# FSI_RX_FSI_RX_CFG_50290000h register map
Vendor: Texas Instruments
Registers are 16-bit, read-write, reset 0x0 unless marked. A register's access mark holds for its fields unless they carry their own. Offsets are as the file gives them; [hi:lo] are bit positions.

## FSI_RX_CFG (part 2 of 2)
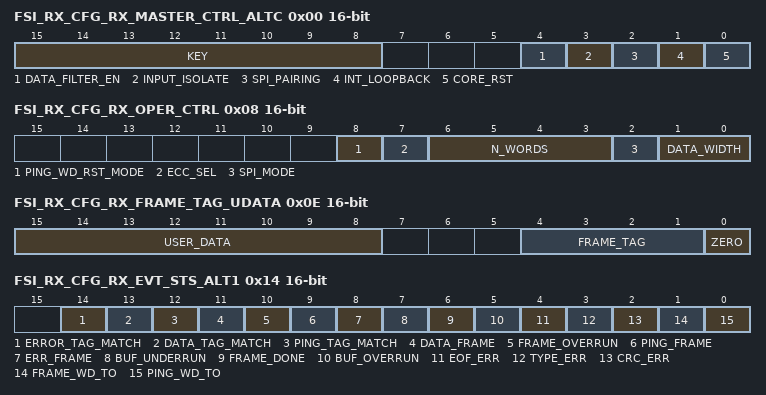
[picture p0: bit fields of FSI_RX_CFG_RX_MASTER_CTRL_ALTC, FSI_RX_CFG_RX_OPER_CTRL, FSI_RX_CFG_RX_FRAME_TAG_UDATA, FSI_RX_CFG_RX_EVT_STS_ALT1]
0x00 FSI_RX_CFG_RX_MASTER_CTRL_ALTC access per field — Receive master control register.
  [15:8] KEY wo — Write Key. In order to write to this register, 0xA5 must be written to this field at the same time. Otherwise, writes are ignored. The key is cleared immediately after Writing, so it must be written again for every change to this register.
  [4] DATA_FILTER_EN rw — Data Filter Enable Bit. 0h[R/W] = Data filtering is disabled. 1h[R/W] = Data filtering is enabled.
  [3] INPUT_ISOLATE rw — When set to 1, the FSI RX inputs [RXCLK, RXD0 and RXD1] will be isolated from what is driven from the device pins and will be held at inactive level of '1'.This isolation facilitates the user to switch the RX inputs to a different set of device pins and hence any potential glitch that could occur during the process of switching will not effect the RX module itself.
  [2] SPI_PAIRING rw — Clock Pairing for SPI-like Behavior Enable bit This bit enables the internal clock pairing with the FSI TX module. This feature internally connects the TXCLK to RXCLK allowing the FSI TX module, acting as a SPI master, to clock data into the receiver and out of the transmitter like a standard SPI module. This configuration is valid when the Module is in SPI mode only [RX_OPER_CTRL.SPI_MODE = 1] 0h[R/W] = SPI clock pairing is not enabled. 1h[R/W] = SPI clock pairing is enabled. The RXCLK will be internally connected to the TXCLK of the corresponding FSI module. Note: The KEY field must contatin 0xA5 for any write to this bit to take effect.
  [1] INT_LOOPBACK rw — Internal Loopback Enable bit This bit enables the internal loopback functionality of the FSI receiver. By enabling this bit, a mux will select the signals coming directly from the corresponding FSI transmitter module rather than from the pins. 0h[R/W] = Internal loopback is disabled. The FSI RX module will receive signals coming from the pins. 1h[R/W] = Internal loopback is enabled. The FSI RX module will receive signals from the directly from FSI TX module rather than the pins. Note: The KEY field must contatin 0xA5 for any write to this bit to take effect.
  [0] CORE_RST rw — Receiver Controller Core Reset bit This bit controls the receiver master core reset. In order to receive any frame, this bit must be cleared. Note: For reset to take affect, the FSI RX module must be held in reset for at least 4 SYSCLK cycles. 0h[R/W] = Receiver core is not in reset and can receive frames. 1h[R/W] = Receiver core is held in reset. Note: The KEY field must contatin 0xA5 for any write to this bit to take effect.
0x08 FSI_RX_CFG_RX_OPER_CTRL — Receive operation control register.
  [8] PING_WD_RST_MODE — Ping Watchdog Timeout Mode Select bit This bit selects the mode by which the ping watchdog counter is reset. The watchdog counter can be reset and restarted only by ping frames or by any received frame. 0h[R/W] = The ping watchdog counter will reset and restart only by ping frames. 1h[R/W] = The ping watchdog counter will reset and restart by any received frame.
  [7] ECC_SEL — ECC Data Width Select bit This bit selects between whether the ECC computation is done on 16-bit or 32-bit words. 0h[R/W] = 32-bit ECC is used. 1h[R/W] = 16-bit ECC is used.
  [6:3] N_WORDS — Number of Words to Receive This field defines the number of words which will be received in a DATA_N_WORD frame. This is a user-defined field that must match the corresponding field in the transmitter. Set this bitfield to be one less than the number of words to be received. This value is only applicable when the frame type received is DATA_N_WORD. 0h[R/W] = 1 data word frame [16-bit data]. 1h[R/W] = 2 data word frame [32-bit data]. .. Fh [R/W] = 16 data word frame [256-bit data].
  [2] SPI_MODE — SPI Mode Enable bit This bit enables and disables the SPI compatibility mode of the FSI RX. The received data must be formatted as an FSI frame in order for the data to properly be received. SPI compatibility mode will allow FSI RX to receive data that is sent using SPI signal format. Refer to the applicable section in the FSI TRM chapter for more information. 0h[R/W] = FSI is in normal mode of operation. 1h[R/W] = FSI is operating in SPI compatibility mode.
  [1:0] DATA_WIDTH — Receive Data Width Select bit These bits decide the number of data lines used for receiving data. 0h[R/W] = Data will be received on one data line, RXD0. 1h[R/W] = Data will be received on two data lines, RXD0 and RXD1. 2h3h[R/W] = Reserved
0x0C FSI_RX_CFG_RX_FRAME_INFO ro — Receive frame control register.
  [3:0] FRAME_TYPE — Received Frame Type This field indicates the type of frame that was successfully received last. 0000b[R/W] = A ping frame was received 0100b[R/W] = A DATA_1_WORD frame was received [16-bit data]. 0101b[R/W] = A DATA_2_WORD frame was received [32-bit data]. 0110b[R/W] = A DATA_4_WORD frame was received [64-bit data]. 0111b[R/W] = A DATA_6_WORD frame was received [96-bit data]. 0011b[R/W] = A DATA_N_WORD frame was received. The N_WORD field will determine the number of words [1 to 16] to be sent. The number of words received must equal the value programmed in RX_OPER_CTRL.N_WORDS. 1111b[R/W] = An error frame was received. This frame can be used during error conditions or any condition where the transmitter wants to signal the receiver for attention. However, the user software is at liberty to use this for any purpose. 0001b0010b and1000bthrough1110bare Reserved and should not be used.
0x0E FSI_RX_CFG_RX_FRAME_TAG_UDATA ro — Receive frame tag and user data register.
  [15:8] USER_DATA — Received User Data This field contains the 8-bit user data field of the last successfully received frame.
  [4:1] FRAME_TAG — Received Frame Tag This field contains the 4-bit frame tag from the last successfully received frame. This is intentionally shifted into bits 4:1 so that the register can be used as a 32-bit address index based on the received tag.
  [0] ZERO — Zero bit This bit will always read as 0. This is intentionally provided to create a 32-bit offset if required. Using the FRAME_TAG and ZERO bits of this register [bits 4:0], application software can directly index into an array of 32-bit data.
0x10 FSI_RX_CFG_RX_DMA_CTRL — Receive DMA event control register.
  [0] DMA_EVT_EN — DMA Event Enable bit This bit will enable a DMA Event to be generated upon the completion of a frame reception. 0h[R/W] = A DMA event will not be generated. 1h[R/W] = A DMA event will be generated upon the reception of a frame. Note: The DMA event will only be generated for data frames.
0x14 FSI_RX_CFG_RX_EVT_STS_ALT1 ro — Receive event and error status flag register.
  [14] ERROR_TAG_MATCH — Error Tag Match Flag This bit indicates that an error frame was received with a tag comparison matching the masked tag reference. Software can also force this bit to get set by Writing to the RX_EVT_FRC register. 0h[R] = No tag-matched error frame received. 1h[R] = A tag-matched error frame has been received. To clear this bit, write to the corresponding bit in the RX_EVT_CLR register.
  [13] DATA_TAG_MATCH — Data Tag Match Flag This bit indicates that a dataframe was received with a tag comparison matching the masked tag reference. Software can also force this bit to get set by Writing to the RX_EVT_FRC register. 0h[R] = No tag-matched data frame received. 1h[R] = A tag-matched data frame has been received. To clear this bit, write to the corresponding bit in the RX_EVT_CLR register.
  [12] PING_TAG_MATCH — Ping Tag Match Flag This bit indicates that a ping frame was received with a tag comparison matching the masked tag reference. Software can also force this bit to get set by Writing to the RX_EVT_FRC register. 0h[R] = No tag-matched ping frame received. 1h[R] = A tag-matched ping frame has been received. To clear this bit, write to the corresponding bit in the RX_EVT_CLR register.
  [11] DATA_FRAME — Data Frame Received Flag This bit indicates that an data frame has been received. Software can also force this bit to get set by Writing to the RX_EVT_FRC register. 0h[R] = No data frame has been received. 1h[R] = A data frame has been received. To clear this bit, write to the corresponding bit in the RX_EVT_CLR register.
  [10] FRAME_OVERRUN — Frame Overrun Flag This bit indicates that a frame overrun condition has occured. This bit gets set to 1 when a new DATA/ERROR frame is received and the corresponding DATA_FRAME_RCVD/ERROR_FRAME_RCVD flag is still set to 1. Software can also force this bit to get set by Writing to the RX_EVT_FRC register. 0h[R] = Frame overrun has not ocurred. 1h[R] = Frame overrun has ocurred. To clear this bit, write to the corresponding bit in the RX_EVT_CLR register.
  [9] PING_FRAME — Ping Frame Received Flag This bit indicates that an ping frame has been received. Software can also force this bit to get set by Writing to the RX_EVT_FRC register. 0h[R] = No ping frame has been received. 1h[R] = A ping frame has been received. To clear this bit, write to the corresponding bit in the RX_EVT_CLR register.
  [8] ERR_FRAME — Error Frame Received Flag This bit indicates that an error frame has been received. Software can also force this bit to get set by Writing to the RX_EVT_FRC register. 0h[R] = No error frame has been received. 1h[R] = An error frame has been received. To clear this bit, write to the corresponding bit in the RX_EVT_CLR register.
  [7] BUF_UNDERRUN — Receive Buffer Underrun Flag This bit indicates that a buffer underrun condition has occured in the receive buffer. This will happen when software reads the buffer which is empty and has no valid data. Software can also force this bit to get set by Writing to the RX_EVT_FRC register. 0h[R] = Receive Buffer Underrun has not ocurred. 1h[R] = Receive Buffer Underrun has ocurred. To clear this bit, write to the corresponding bit in the RX_EVT_CLR register.
  [6] FRAME_DONE — Frame Done Flag This bit indicates that a frame has been successfully received without error. Software can also force this bit to get set by Writing to the RX_EVT_FRC register. 0h[R] = No frame has been successfully received. 1h[R] = A frame has been successfully received. To clear this bit, write to the corresponding bit in the RX_EVT_CLR register.
  [5] BUF_OVERRUN — Receive Buffer Overrun Flag This bit indicates that a buffer overrun condition has occured in the receive buffer. Software can also force this bit to get set by Writing to the RX_EVT_FRC register. 0h[R] = Receive buffer overrun has not ocurred. 1h[R] = Receive buffer overrun has ocurred. To clear this bit, write to the corresponding bit in the RX_EVT_CLR register.
  [4] EOF_ERR — End-of-Frame Error Flag This bit indicates that an invalid end-of-frame bit pattern has been received. Software can also force this bit to get set by Writing to the RX_EVT_FRC register. 0h[R] = Invalid end-of-frame has not been received. 1h[R] = Invalid end-of-frame has been received To clear this bit, write to the corresponding bit in the RX_EVT_CLR register.
  [3] TYPE_ERR — Frame Type Error Flag This bit inditcates that an invalid frame type has been received. Software can also force this bit to get set by Writing to the RX_EVT_FRC register. 0h[R] = Invalid frame type has not been received. 1h[R] = Invalid frame type has been received To clear this bit, write to the corresponding bit in the RX_EVT_CLR register.
  [2] CRC_ERR — CRC Error Flag This bit indicates that a CRC error has occured. A CRC error will be generated on a data frame where the received CRC and the computed CRC do not match. Software can also force this bit to get set by Writing to the RX_EVT_FRC register. 0h[R] = CRC error has not occured. 1h[R] = CRC error has occured. To clear this bit, write to the corresponding bit in the RX_EVT_CLR register.
  [1] FRAME_WD_TO — Frame Watchdog Timeout Flag This bit indicates that the frame watchdog timer has timed out. Software can also force this bit to get set by Writing to the RX_EVT_FRC register. 0h[R] = Frame watchdog timeout has not occured. 1h[R] = Frame watchdog timeout has occured. To clear this bit, write to the corresponding bit in the RX_EVT_CLR register.
  [0] PING_WD_TO — Ping Watchdog Timeout Flag This bit indicates that the ping watchdog timer has timed out. Software can also force this bit to get set by Writing to the RX_EVT_FRC register. 0h[R] = Ping watchdog timeout has not occured. 1h[R] = Ping watchdog timeout has occured. To clear this bit, write to the corresponding bit in the RX_EVT_CLR register.
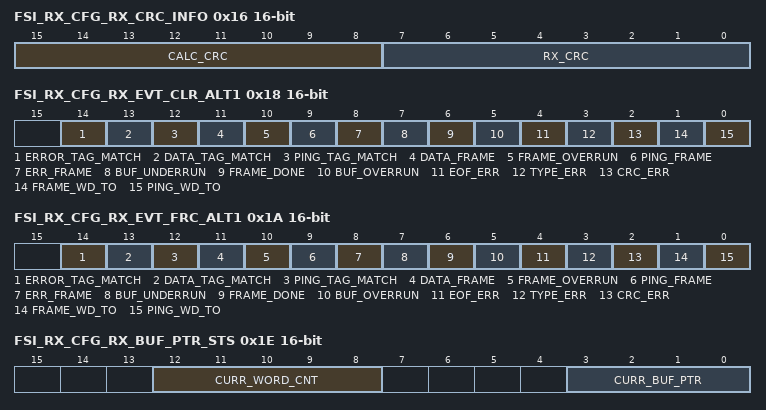
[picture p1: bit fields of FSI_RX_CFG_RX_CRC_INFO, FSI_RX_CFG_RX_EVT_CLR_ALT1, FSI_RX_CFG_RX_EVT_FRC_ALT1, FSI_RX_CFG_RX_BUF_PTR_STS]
0x16 FSI_RX_CFG_RX_CRC_INFO ro — Receive CRC info of received and computed CRC.
  [15:8] CALC_CRC — Harware Calculated CRC Value This bitfield contains the CRC value that was calculated on the last received data. The contents of this bitfield are valid only when data frames are received. Note: The contents of this bitfield are invalid for ping and error frames.
  [7:0] RX_CRC — Received CRC Value This bitfield contains the CRC value that was last received a frame. The contents of this bitfield are valid only when data frames are received. Note: The contents of this bitfield are invalid for ping and error frames.
0x18 FSI_RX_CFG_RX_EVT_CLR_ALT1 wo — Receive event and error clear register.
  [14] ERROR_TAG_MATCH — Error Tag Match Glag Clear bit This bit clears the corresponding bit in the RX_EVT_STS register. 0h[W] = Writing a 0 to this bit will have no effect. 1h[W] = Writing a 1 to this bit will clear the corresponding bit in the RX_EVT_STS register to 0.
  [13] DATA_TAG_MATCH — Data Tag Match Flag Clear bit This bit clears the corresponding bit in the RX_EVT_STS register. 0h[W] = Writing a 0 to this bit will have no effect. 1h[W] = Writing a 1 to this bit will clear the corresponding bit in the RX_EVT_STS register to 0.
  [12] PING_TAG_MATCH — Ping Tag Match Flag Clear bit This bit clears the corresponding bit in the RX_EVT_STS register. 0h[W] = Writing a 0 to this bit will have no effect. 1h[W] = Writing a 1 to this bit will clear the corresponding bit in the RX_EVT_STS register to 0.
  [11] DATA_FRAME — Data Frame Received Flag Clear bit This bit clears the corresponding bit in the RX_EVT_STS register. 0h[W] = Writing a 0 to this bit will have no effect. 1h[W] = Writing a 1 to this bit will clear the corresponding bit in the RX_EVT_STS register to 0.
  [10] FRAME_OVERRUN — Frame Overrun Flag Clear bit This bit clears the corresponding bit in the RX_EVT_STS register. 0h[W] = Writing a 0 to this bit will have no effect. 1h[W] = Writing a 1 to this bit will clear the corresponding bit in the RX_EVT_STS register to 0.
  [9] PING_FRAME — Ping Frame Received Flag Clear bit This bit clears the corresponding bit in the RX_EVT_STS register. 0h[W] = Writing a 0 to this bit will have no effect. 1h[W] = Writing a 1 to this bit will clear the corresponding bit in the RX_EVT_STS register to 0.
  [8] ERR_FRAME — Error Frame Received Flag Clear bit This bit clears the corresponding bit in the RX_EVT_STS register. 0h[W] = Writing a 0 to this bit will have no effect. 1h[W] = Writing a 1 to this bit will clear the corresponding bit in the RX_EVT_STS register to 0.
  [7] BUF_UNDERRUN — Receive Buffer Underrun Flag Clear bit This bit clears the corresponding bit in the RX_EVT_STS register. 0h[R/W] = Writing a 0 to this bit will have no effect. 1h[R/W] = Writing a 1 to this bit will clear the corresponding bit in the RX_EVT_STS register to 0.
  [6] FRAME_DONE — Frame Done Flag Clear bit This bit clears the corresponding bit in the RX_EVT_STS register. 0h[W] = Writing a 0 to this bit will have no effect. 1h[W] = Writing a 1 to this bit will clear the corresponding bit in the RX_EVT_STS register to 0.
  [5] BUF_OVERRUN — Receive Buffer Overrun Flag Clear bit This bit clears the corresponding bit in the RX_EVT_STS register. 0h[W] = Writing a 0 to this bit will have no effect. 1h[W] = Writing a 1 to this bit will clear the corresponding bit in the RX_EVT_STS register to 0.
  [4] EOF_ERR — End-of-Frame Error Flag Clear bit This bit clears the corresponding bit in the RX_EVT_STS register. 0h[W] = Writing a 0 to this bit will have no effect. 1h[W] = Writing a 1 to this bit will clear the corresponding bit in the RX_EVT_STS register to 0.
  [3] TYPE_ERR — Frame Type Error Flag Clear bit This bit clears the corresponding bit in the RX_EVT_STS register. 0h[W] = Writing a 0 to this bit will have no effect. 1h[W] = Writing a 1 to this bit will clear the corresponding bit in the RX_EVT_STS register to 0.
  [2] CRC_ERR — CRC Error Flag Clear bit This bit clears the corresponding bit in the RX_EVT_STS register. 0h[W] = Writing a 0 to this bit will have no effect. 1h[W] = Writing a 1 to this bit will clear the corresponding bit in the RX_EVT_STS register to 0.
  [1] FRAME_WD_TO — Frame Watchdog Timeout Flag Clear bit This bit clears the corresponding bit in the RX_EVT_STS register. 0h[W] = Writing a 0 to this bit will have no effect. 1h[W] = Writing a 1 to this bit will clear the corresponding bit in the RX_EVT_STS register to 0.
  [0] PING_WD_TO — Ping Watchdog Timeout Flag Clear bit This bit clears the corresponding bit in the RX_EVT_STS register. 0h[W] = Writing a 0 to this bit will have no effect. 1h[W] = Writing a 1 to this bit will clear the corresponding bit in the RX_EVT_STS register to 0.
0x1A FSI_RX_CFG_RX_EVT_FRC_ALT1 wo — Receive event and error flag force register.
  [14] ERROR_TAG_MATCH — Error Tag Match Flag Force bit This bit will cause the corresponding bit in the RX_EVT_STS register to get set. The purpose of this register is to allow software to simulate the effect of the event and test the associated software/ISR. 0h[W] = Writing a 0 to this bit will have no effect. 1h[W] = Force the corresponding bit in the RX_EVT_STS Register.
  [13] DATA_TAG_MATCH — Data Tag Match Flag Force bit This bit will cause the corresponding bit in the RX_EVT_STS register to get set. The purpose of this register is to allow software to simulate the effect of the event and test the associated software/ISR. 0h[W] = Writing a 0 to this bit will have no effect. 1h[W] = Force the corresponding bit in the RX_EVT_STS Register.
  [12] PING_TAG_MATCH — Ping Tag Match Flag Force bit This bit will cause the corresponding bit in the RX_EVT_STS register to get set. The purpose of this register is to allow software to simulate the effect of the event and test the associated software/ISR. 0h[W] = Writing a 0 to this bit will have no effect. 1h[W] = Force the corresponding bit in the RX_EVT_STS Register.
  [11] DATA_FRAME — Data Frame Received Flag Force bit This bit will cause the corresponding bit in the RX_EVT_STS register to get set. The purpose of this register is to allow software to simulate the effect of the event and test the associated software/ISR. 0h[W] = Writing a 0 to this bit will have no effect. 1h[W] = Force the corresponding bit in the RX_EVT_STS Register.
  [10] FRAME_OVERRUN — Frame Overrun Flag Force bit This bit will cause the corresponding bit in the RX_EVT_STS register to get set. The purpose of this register is to allow software to simulate the effect of the event and test the associated software/ISR. 0h[W] = Writing a 0 to this bit will have no effect. 1h[W] = Force the corresponding bit in the RX_EVT_STS Register.
  [9] PING_FRAME — Ping Frame Received Flag Force bit This bit will cause the corresponding bit in the RX_EVT_STS register to get set. The purpose of this register is to allow software to simulate the effect of the event and test the associated software/ISR. 0h[W] = Writing a 0 to this bit will have no effect. 1h[W] = Force the corresponding bit in the RX_EVT_STS Register.
  [8] ERR_FRAME — Error Frame Received Flag Force bit This bit will cause the corresponding bit in the RX_EVT_STS register to get set. The purpose of this register is to allow software to simulate the effect of the event and test the associated software/ISR. 0h[W] = Writing a 0 to this bit will have no effect. 1h[W] = Force the corresponding bit in the RX_EVT_STS Register.
  [7] BUF_UNDERRUN — Receive Buffer Underrun Flag Force bit This bit will cause the corresponding bit in the RX_EVT_STS register to get set. The purpose of this register is to allow software to simulate the effect of the event and test the associated software/ISR. 0h[W] = Writing a 0 to this bit will have no effect. 1h[W] = Force the corresponding bit in the RX_EVT_STS Register.
  [6] FRAME_DONE — Frame Done Flag Force bit This bit will cause the corresponding bit in the RX_EVT_STS register to get set. The purpose of this register is to allow software to simulate the effect of the event and test the associated software/ISR. 0h[W] = Writing a 0 to this bit will have no effect. 1h[W] = Force the corresponding bit in the RX_EVT_STS Register.
  [5] BUF_OVERRUN — Receive Buffer Overrun Flag Force bit This bit will cause the corresponding bit in the RX_EVT_STS register to get set. The purpose of this register is to allow software to simulate the effect of the event and test the associated software/ISR. 0h[W] = Writing a 0 to this bit will have no effect. 1h[W] = Force the corresponding bit in the RX_EVT_STS Register.
  [4] EOF_ERR — End-of-Frame Error Flag Force bit This bit will cause the corresponding bit in the RX_EVT_STS register to get set. The purpose of this register is to allow software to simulate the effect of the event and test the associated software/ISR. 0h[W] = Writing a 0 to this bit will have no effect. 1h[W] = Force the corresponding bit in the RX_EVT_STS Register.
  [3] TYPE_ERR — Frame Type Error Flag Force bit This bit will cause the corresponding bit in the RX_EVT_STS register to get set. The purpose of this register is to allow software to simulate the effect of the event and test the associated software/ISR. 0h[W] = Writing a 0 to this bit will have no effect. 1h[W] = Force the corresponding bit in the RX_EVT_STS Register.
  [2] CRC_ERR — CRC Error Flag Force bit This bit will cause the corresponding bit in the RX_EVT_STS register to get set. The purpose of this register is to allow software to simulate the effect of the event and test the associated software/ISR. 0h[W] = Writing a 0 to this bit will have no effect. 1h[W] = Force the corresponding bit in the RX_EVT_STS Register.
  [1] FRAME_WD_TO — Frame Watchdog Timeout Flag Force bit This bit will cause the corresponding bit in the RX_EVT_STS register to get set. The purpose of this register is to allow software to simulate the effect of the event and test the associated software/ISR. 0h[W] = Writing a 0 to this bit will have no effect. 1h[W] = Force the corresponding bit in the RX_EVT_STS Register.
  [0] PING_WD_TO — Ping Watchdog Timeout Flag Force bit This bit will cause the corresponding bit in the RX_EVT_STS register to get set. The purpose of this register is to allow software to simulate the effect of the event and test the associated software/ISR. 0h[W] = Writing a 0 to this bit will have no effect. 1h[W] = Force the corresponding bit in the RX_EVT_STS Register.
0x1C FSI_RX_CFG_RX_BUF_PTR_LOAD — Receive buffer pointer load register.
  [3:0] BUF_PTR_LOAD — Buffer Pointer Load. This is the value to be loaded into the receive word pointer when written. This is to allow software to force the receiver to start storing the received data starting at a specific location in the buffer. NOTE: The value of the CURR_BUF_PTR in the RX_BUF_PTR_STS will not get reflected immediately. This will take effect only when there is a valid receive operation with incoming clocks after [3 RXCLK + 3 SYCLK] cycles.
0x1E FSI_RX_CFG_RX_BUF_PTR_STS ro — Receive buffer pointer status register.
  [12:8] CURR_WORD_CNT — Words Available in the Receive Buffer This bitfield indicates the number of valid data words present in the receive buffer that have not been read by the application software. This bitfield is only valid when there is no active transfer. Note: This value will not be valid if there has been a buffer overrun or underrun condition.
  [3:0] CURR_BUF_PTR — Current Buffer Pointer Index This bitfield will show the current index of the buffer pointer. This value is only valid when there is no active transmission.
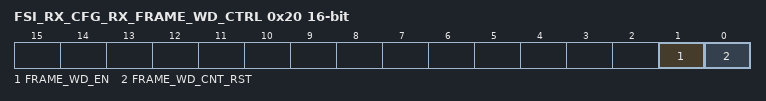
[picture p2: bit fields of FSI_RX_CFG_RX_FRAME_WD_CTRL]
0x20 FSI_RX_CFG_RX_FRAME_WD_CTRL — Receive frame watchdog control register.
  [1] FRAME_WD_EN — Frame Watchdog Counter Enable bit This bit will enable or disable the frame watchdog counter. The counter [RX_FRAME_WD_CNT] will begin counting from 0 when a valid start-of-frame pattern is received. When the reference value [RX_FRAME_WD_REF] is reached, it will generate a frame watchdog timeout event [RX_EVT_STS.FRAME_WD_TO] and the counter value will reset to 0 and continue counting on the next valid start-of-frame. 0h[R/W] = The frame watchdog counter is disabled and not running. 1h[R/W] = The frame watchdog counter logic is enabled and running.
  [0] FRAME_WD_CNT_RST — Frame Watchdog Counter Reset bit This bit will reset the frame watchdog counter to 0. Writing a 1 to this bit will reset the frame watchdog counter to 0. The counter will stay in reset as long as this bit is set to 1. This bit needs to be cleared to 0 to use the counter 0h[R/W] = Clear the FRAME_WD_CNT_RST. 1h[W] = The frame watchdog counter will be reset to 0.
0x24 FSI_RX_CFG_RX_FRAME_WD_REF 32-bit — Receive frame watchdog counter reference.
  [31:0] FRAME_WD_REF — Frame Watchdog Counter Reference Value This is the 32-bit reference value for the frame watchdog timeout counter. The counter will count up starting from 0 at a valid start-of-frame pattern and continue counting until this value is reached.
